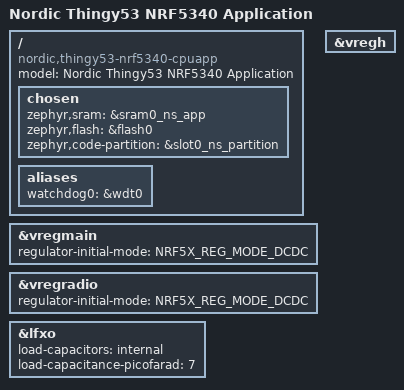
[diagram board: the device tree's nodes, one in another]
/*
 * Copyright (c) 2021 Nordic Semiconductor ASA
 *
 * SPDX-License-Identifier: Apache-2.0
 */

/dts-v1/;
#include <nordic/nrf5340_cpuappns_qkaa.dtsi>
#include "thingy53_nrf5340_common.dtsi"

/ {
	model = "Nordic Thingy53 NRF5340 Application";
	compatible = "nordic,thingy53-nrf5340-cpuapp";

	chosen {
		zephyr,sram = &sram0_ns_app;
		zephyr,flash = &flash0;
		zephyr,code-partition = &slot0_ns_partition;
	};

	aliases {
		watchdog0 = &wdt0;
	};
};

&vregmain {
	regulator-initial-mode = <NRF5X_REG_MODE_DCDC>;
};

&vregradio {
	regulator-initial-mode = <NRF5X_REG_MODE_DCDC>;
};

&vregh {
	status = "okay";
};

&lfxo {
	load-capacitors = "internal";
	load-capacitance-picofarad = <7>;
};
